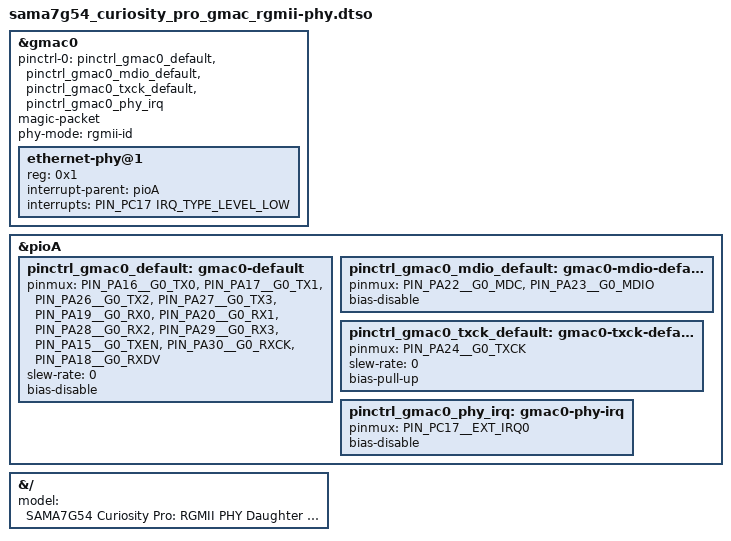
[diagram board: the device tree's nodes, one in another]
// SPDX-License-Identifier: (GPL-2.0+ OR MIT)
/*
 * Device Tree file for SAMA7G54 Curiosity Pro board overlay blob for
 * Gigabit PHY EDS2 daughter card.
 *
 * Copyright (C) 2026 Microchip Technology Inc. and its subsidiaries
 *
 * Author: Varshini Rajendran <varshini.rajendran@microchip.com>
 *
 */
/dts-v1/;
/plugin/;

#include <dt-bindings/interrupt-controller/irq.h>
#include <dt-bindings/mfd/atmel-flexcom.h>
#include <dt-bindings/pinctrl/at91.h>
#include "sama7g5-pinfunc.h"

&gmac0 {
	#address-cells = <1>;
	#size-cells = <0>;
	pinctrl-names = "default";
	pinctrl-0 = <&pinctrl_gmac0_default
		     &pinctrl_gmac0_mdio_default
		     &pinctrl_gmac0_txck_default
		     &pinctrl_gmac0_phy_irq>;
	magic-packet;
	phy-mode = "rgmii-id";
	status = "okay";

	ethernet-phy@1 {
		reg = <0x1>;
		interrupt-parent = <&pioA>;
		interrupts = <PIN_PC17 IRQ_TYPE_LEVEL_LOW>;
	};
};

&pioA {
	pinctrl_gmac0_default: gmac0-default {
		pinmux = <PIN_PA16__G0_TX0>,
			 <PIN_PA17__G0_TX1>,
			 <PIN_PA26__G0_TX2>,
			 <PIN_PA27__G0_TX3>,
			 <PIN_PA19__G0_RX0>,
			 <PIN_PA20__G0_RX1>,
			 <PIN_PA28__G0_RX2>,
			 <PIN_PA29__G0_RX3>,
			 <PIN_PA15__G0_TXEN>,
			 <PIN_PA30__G0_RXCK>,
			 <PIN_PA18__G0_RXDV>;
		slew-rate = <0>;
		bias-disable;
	};

	pinctrl_gmac0_mdio_default: gmac0-mdio-default {
		pinmux = <PIN_PA22__G0_MDC>,
			 <PIN_PA23__G0_MDIO>;
		bias-disable;
	};

	pinctrl_gmac0_txck_default: gmac0-txck-default {
		pinmux = <PIN_PA24__G0_TXCK>;
		slew-rate = <0>;
		bias-pull-up;
	};

	pinctrl_gmac0_phy_irq: gmac0-phy-irq {
		pinmux = <PIN_PC17__EXT_IRQ0>;
		bias-disable;
	};
};

&{/} {
	model = "SAMA7G54 Curiosity Pro: RGMII PHY Daughter Card";
};
